# PIC32MK1024MCF064 register map
Vendor: Microchip
Registers are 32-bit, read-write, reset 0x0 unless marked. A register's access mark holds for its fields unless they carry their own. Addresses are absolute, and some are shared; only a register's first bit layout is shown; [hi:lo] are bit positions; {n}, {i} and the like mark numbered series.

## PORTG
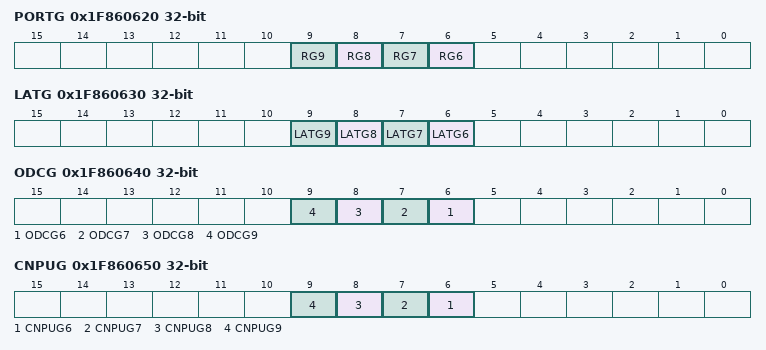
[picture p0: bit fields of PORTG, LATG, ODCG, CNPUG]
0x1F860620 PORTG reset not defined — (power-on value ----------------------xxxx------)
  [n] RG{n} (n=6..9)
0x1F860630 LATG reset not defined — (power-on value ----------------------xxxx------)
  [n] LATG{n} (n=6..9)
0x1F860640 ODCG
  [n] ODCG{n} (n=6..9)
0x1F860650 CNPUG
  [n] CNPUG{n} (n=6..9)
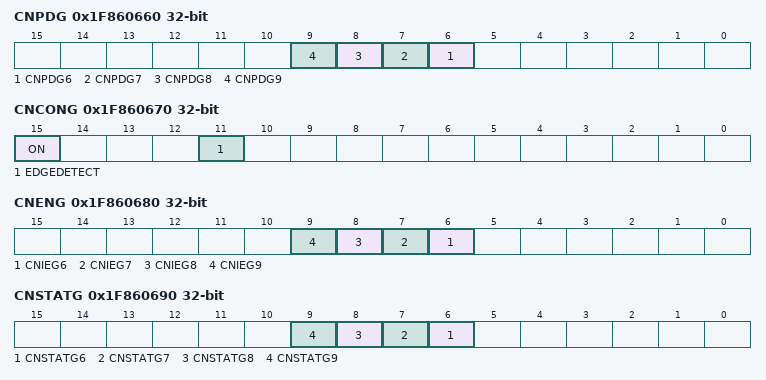
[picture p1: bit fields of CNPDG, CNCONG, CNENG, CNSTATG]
0x1F860660 CNPDG
  [n] CNPDG{n} (n=6..9)
0x1F860670 CNCONG
  [15] ON, [11] EDGEDETECT
0x1F860680 CNENG
  [n] CNIEG{n} (n=6..9)
0x1F860690 CNSTATG
  [n] CNSTATG{n} (n=6..9)
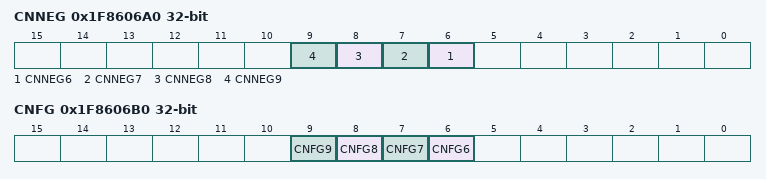
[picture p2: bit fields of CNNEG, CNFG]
0x1F8606A0 CNNEG
  [n] CNNEG{n} (n=6..9)
0x1F8606B0 CNFG
  [n] CNFG{n} (n=6..9)

## CAN1
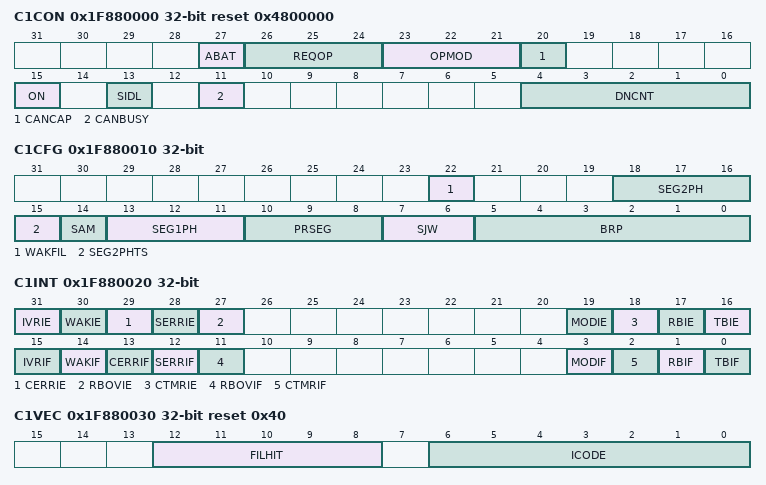
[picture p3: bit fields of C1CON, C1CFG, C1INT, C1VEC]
0x1F880000 C1CON reset 0x4800000
  [27] ABAT — (can only be set)
  [26:24] REQOP
  [23:21] OPMOD ro
  [20] CANCAP
  [15] ON
  [13] SIDL
  [11] CANBUSY ro
  [4:0] DNCNT
0x1F880010 C1CFG
  [22] WAKFIL, [18:16] SEG2PH, [15] SEG2PHTS, [14] SAM, [13:11] SEG1PH, [10:8] PRSEG, [7:6] SJW, [5:0] BRP
0x1F880020 C1INT
  [31] IVRIE, [30] WAKIE, [29] CERRIE, [28] SERRIE, [27] RBOVIE, [19] MODIE, [18] CTMRIE, [17] RBIE, [16] TBIE, [15] IVRIF, [14] WAKIF, [13] CERRIF, [12] SERRIF, [11] RBOVIF, [3] MODIF, [2] CTMRIF, [1] RBIF, [0] TBIF
0x1F880030 C1VEC ro reset 0x40
  [12:8] FILHIT, [6:0] ICODE
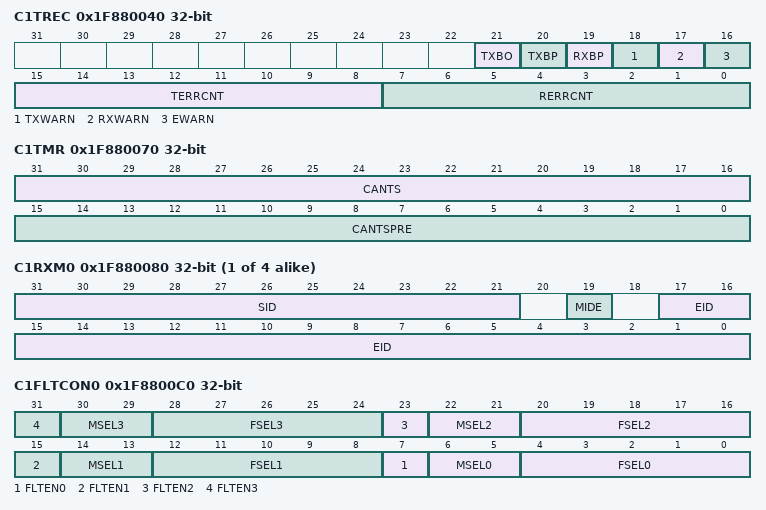
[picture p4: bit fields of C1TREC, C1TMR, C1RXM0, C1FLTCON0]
0x1F880040 C1TREC ro
  [21] TXBO, [20] TXBP, [19] RXBP, [18] TXWARN, [17] RXWARN, [16] EWARN, [15:8] TERRCNT, [7:0] RERRCNT
0x1F880050 C1FSTAT ro
  [15:0] FIFOIP
0x1F880060 C1RXOVF ro
  [15:0] RXOVF
0x1F880070 C1TMR
  [31:16] CANTS, [15:0] CANTSPRE
{0x1F880080+0x10*i} C1RXM{i} (i=0..3)
  [31:21] SID, [19] MIDE, [17:0] EID
0x1F8800C0 C1FLTCON0
  [8n+7] FLTEN{n} (n=0..3), [8n+6:8n+5] MSEL{n} (n=0..3), [8n+4:8n] FSEL{n} (n=0..3)
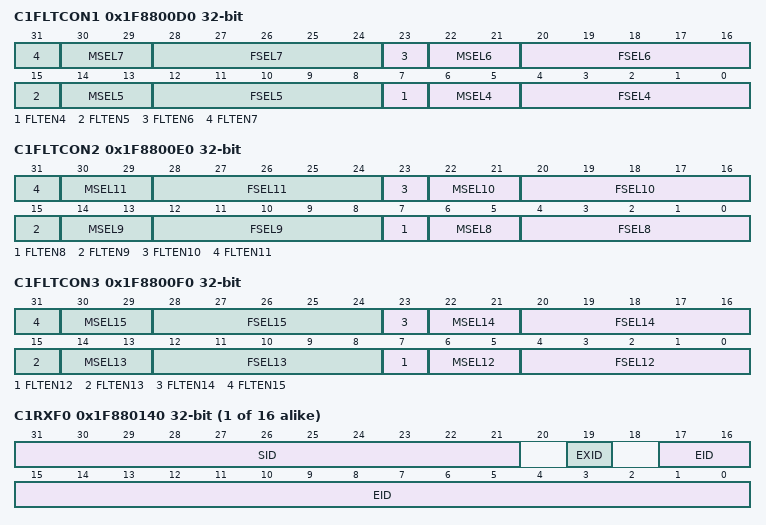
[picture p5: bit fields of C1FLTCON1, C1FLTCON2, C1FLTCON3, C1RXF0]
0x1F8800D0 C1FLTCON1
  [8n-25] FLTEN{n} (n=4..7), [8n-26:8n-27] MSEL{n} (n=4..7), [8n-28:8n-32] FSEL{n} (n=4..7)
0x1F8800E0 C1FLTCON2
  [8n-57] FLTEN{n} (n=8..11), [8n-58:8n-59] MSEL{n} (n=8..11), [8n-60:8n-64] FSEL{n} (n=8..11)
0x1F8800F0 C1FLTCON3
  [8n-89] FLTEN{n} (n=12..15), [8n-90:8n-91] MSEL{n} (n=12..15), [8n-92:8n-96] FSEL{n} (n=12..15)
{0x1F880140+0x10*i} C1RXF{i} reset not defined (i=0..15) — (power-on value xxxxxxxxxxx0x0xxxxxxxxxxxxxxxxxx)
  [31:21] SID, [19] EXID, [17:0] EID
0x1F880340 C1FIFOBA
  [31:2] FIFOBA
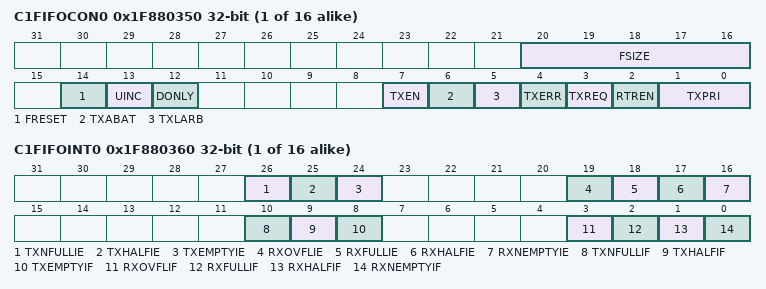
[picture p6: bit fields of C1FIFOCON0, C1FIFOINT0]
{0x1F880350+0x40*i} C1FIFOCON{i} (i=0..15)
  [20:16] FSIZE, [14] FRESET, [13] UINC, [12] DONLY, [7] TXEN, [6] TXABAT, [5] TXLARB, [4] TXERR, [3] TXREQ, [2] RTREN, [1:0] TXPRI
{0x1F880360+0x40*i} C1FIFOINT{i} (i=0..15)
  [26] TXNFULLIE, [25] TXHALFIE, [24] TXEMPTYIE, [19] RXOVFLIE, [18] RXFULLIE, [17] RXHALFIE, [16] RXNEMPTYIE, [10] TXNFULLIF ro, [9] TXHALFIF ro, [8] TXEMPTYIF ro, [3] RXOVFLIF, [2] RXFULLIF ro, [1] RXHALFIF ro, [0] RXNEMPTYIF ro
{0x1F880370+0x40*i} C1FIFOUA{i} ro reset not defined (i=0..15) — (power-on value xxxxxxxxxxxxxxxxxxxxxxxxxxxxxx00)
  [31:2] FIFOUA
{0x1F880380+0x40*i} C1FIFOCI{i} ro (i=0..15)
  [4:0] CFIFOCI

## CAN2
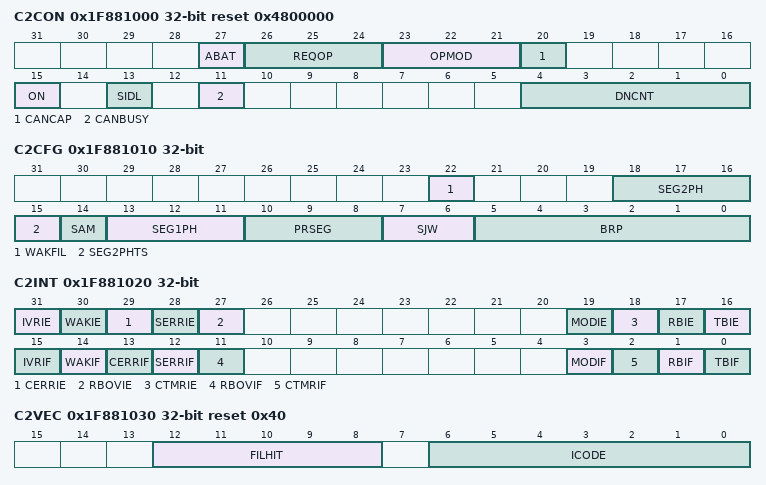
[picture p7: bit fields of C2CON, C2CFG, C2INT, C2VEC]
0x1F881000 C2CON reset 0x4800000
  [27] ABAT — (can only be set)
  [26:24] REQOP
  [23:21] OPMOD ro
  [20] CANCAP
  [15] ON
  [13] SIDL
  [11] CANBUSY ro
  [4:0] DNCNT
0x1F881010 C2CFG
  [22] WAKFIL, [18:16] SEG2PH, [15] SEG2PHTS, [14] SAM, [13:11] SEG1PH, [10:8] PRSEG, [7:6] SJW, [5:0] BRP
0x1F881020 C2INT
  [31] IVRIE, [30] WAKIE, [29] CERRIE, [28] SERRIE, [27] RBOVIE, [19] MODIE, [18] CTMRIE, [17] RBIE, [16] TBIE, [15] IVRIF, [14] WAKIF, [13] CERRIF, [12] SERRIF, [11] RBOVIF, [3] MODIF, [2] CTMRIF, [1] RBIF, [0] TBIF
0x1F881030 C2VEC ro reset 0x40
  [12:8] FILHIT, [6:0] ICODE
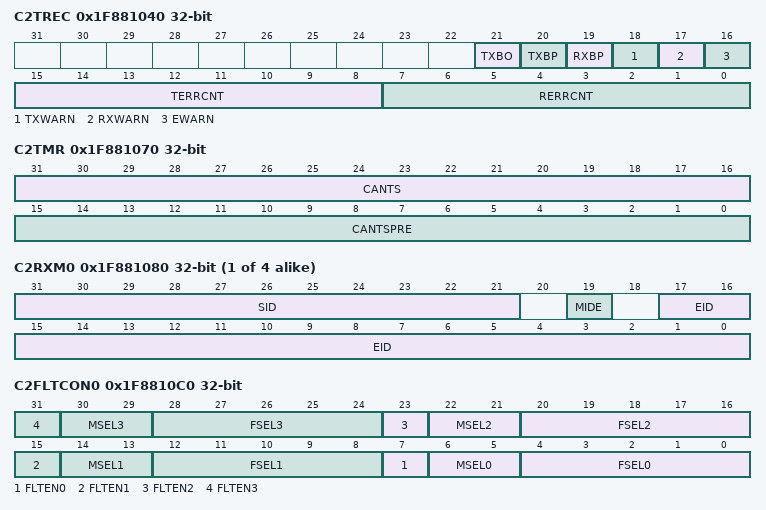
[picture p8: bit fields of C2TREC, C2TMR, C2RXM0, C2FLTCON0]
0x1F881040 C2TREC ro
  [21] TXBO, [20] TXBP, [19] RXBP, [18] TXWARN, [17] RXWARN, [16] EWARN, [15:8] TERRCNT, [7:0] RERRCNT
0x1F881050 C2FSTAT ro
  [15:0] FIFOIP
0x1F881060 C2RXOVF ro
  [15:0] RXOVF
0x1F881070 C2TMR
  [31:16] CANTS, [15:0] CANTSPRE
{0x1F881080+0x10*i} C2RXM{i} (i=0..3)
  [31:21] SID, [19] MIDE, [17:0] EID
0x1F8810C0 C2FLTCON0
  [8n+7] FLTEN{n} (n=0..3), [8n+6:8n+5] MSEL{n} (n=0..3), [8n+4:8n] FSEL{n} (n=0..3)
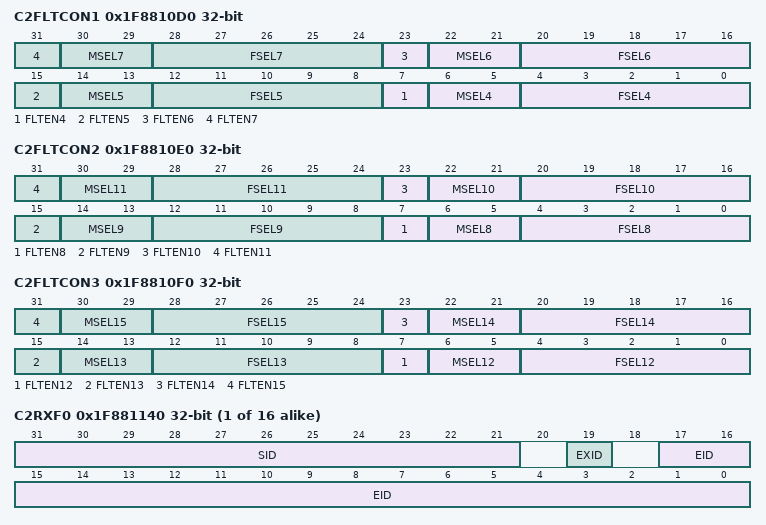
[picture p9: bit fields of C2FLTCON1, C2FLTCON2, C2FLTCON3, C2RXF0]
0x1F8810D0 C2FLTCON1
  [8n-25] FLTEN{n} (n=4..7), [8n-26:8n-27] MSEL{n} (n=4..7), [8n-28:8n-32] FSEL{n} (n=4..7)
0x1F8810E0 C2FLTCON2
  [8n-57] FLTEN{n} (n=8..11), [8n-58:8n-59] MSEL{n} (n=8..11), [8n-60:8n-64] FSEL{n} (n=8..11)
0x1F8810F0 C2FLTCON3
  [8n-89] FLTEN{n} (n=12..15), [8n-90:8n-91] MSEL{n} (n=12..15), [8n-92:8n-96] FSEL{n} (n=12..15)
{0x1F881140+0x10*i} C2RXF{i} reset not defined (i=0..15) — (power-on value xxxxxxxxxxx0x0xxxxxxxxxxxxxxxxxx)
  [31:21] SID, [19] EXID, [17:0] EID
0x1F881340 C2FIFOBA
  [31:2] FIFOBA
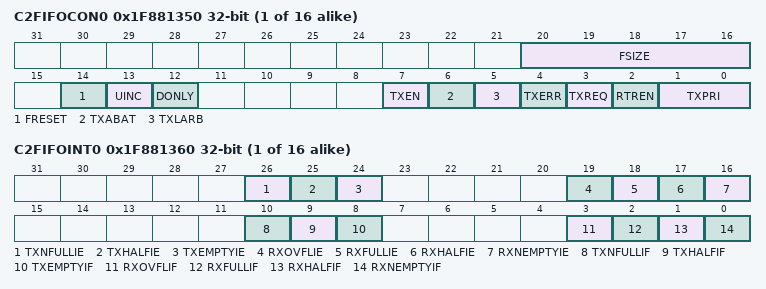
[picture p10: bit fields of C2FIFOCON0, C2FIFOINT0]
{0x1F881350+0x40*i} C2FIFOCON{i} (i=0..15)
  [20:16] FSIZE, [14] FRESET, [13] UINC, [12] DONLY, [7] TXEN, [6] TXABAT, [5] TXLARB, [4] TXERR, [3] TXREQ, [2] RTREN, [1:0] TXPRI
{0x1F881360+0x40*i} C2FIFOINT{i} (i=0..15)
  [26] TXNFULLIE, [25] TXHALFIE, [24] TXEMPTYIE, [19] RXOVFLIE, [18] RXFULLIE, [17] RXHALFIE, [16] RXNEMPTYIE, [10] TXNFULLIF ro, [9] TXHALFIF ro, [8] TXEMPTYIF ro, [3] RXOVFLIF, [2] RXFULLIF ro, [1] RXHALFIF ro, [0] RXNEMPTYIF ro
{0x1F881370+0x40*i} C2FIFOUA{i} ro reset not defined (i=0..15) — (power-on value xxxxxxxxxxxxxxxxxxxxxxxxxxxxxx00)
  [31:2] FIFOUA
{0x1F881380+0x40*i} C2FIFOCI{i} ro (i=0..15)
  [4:0] CFIFOCI
